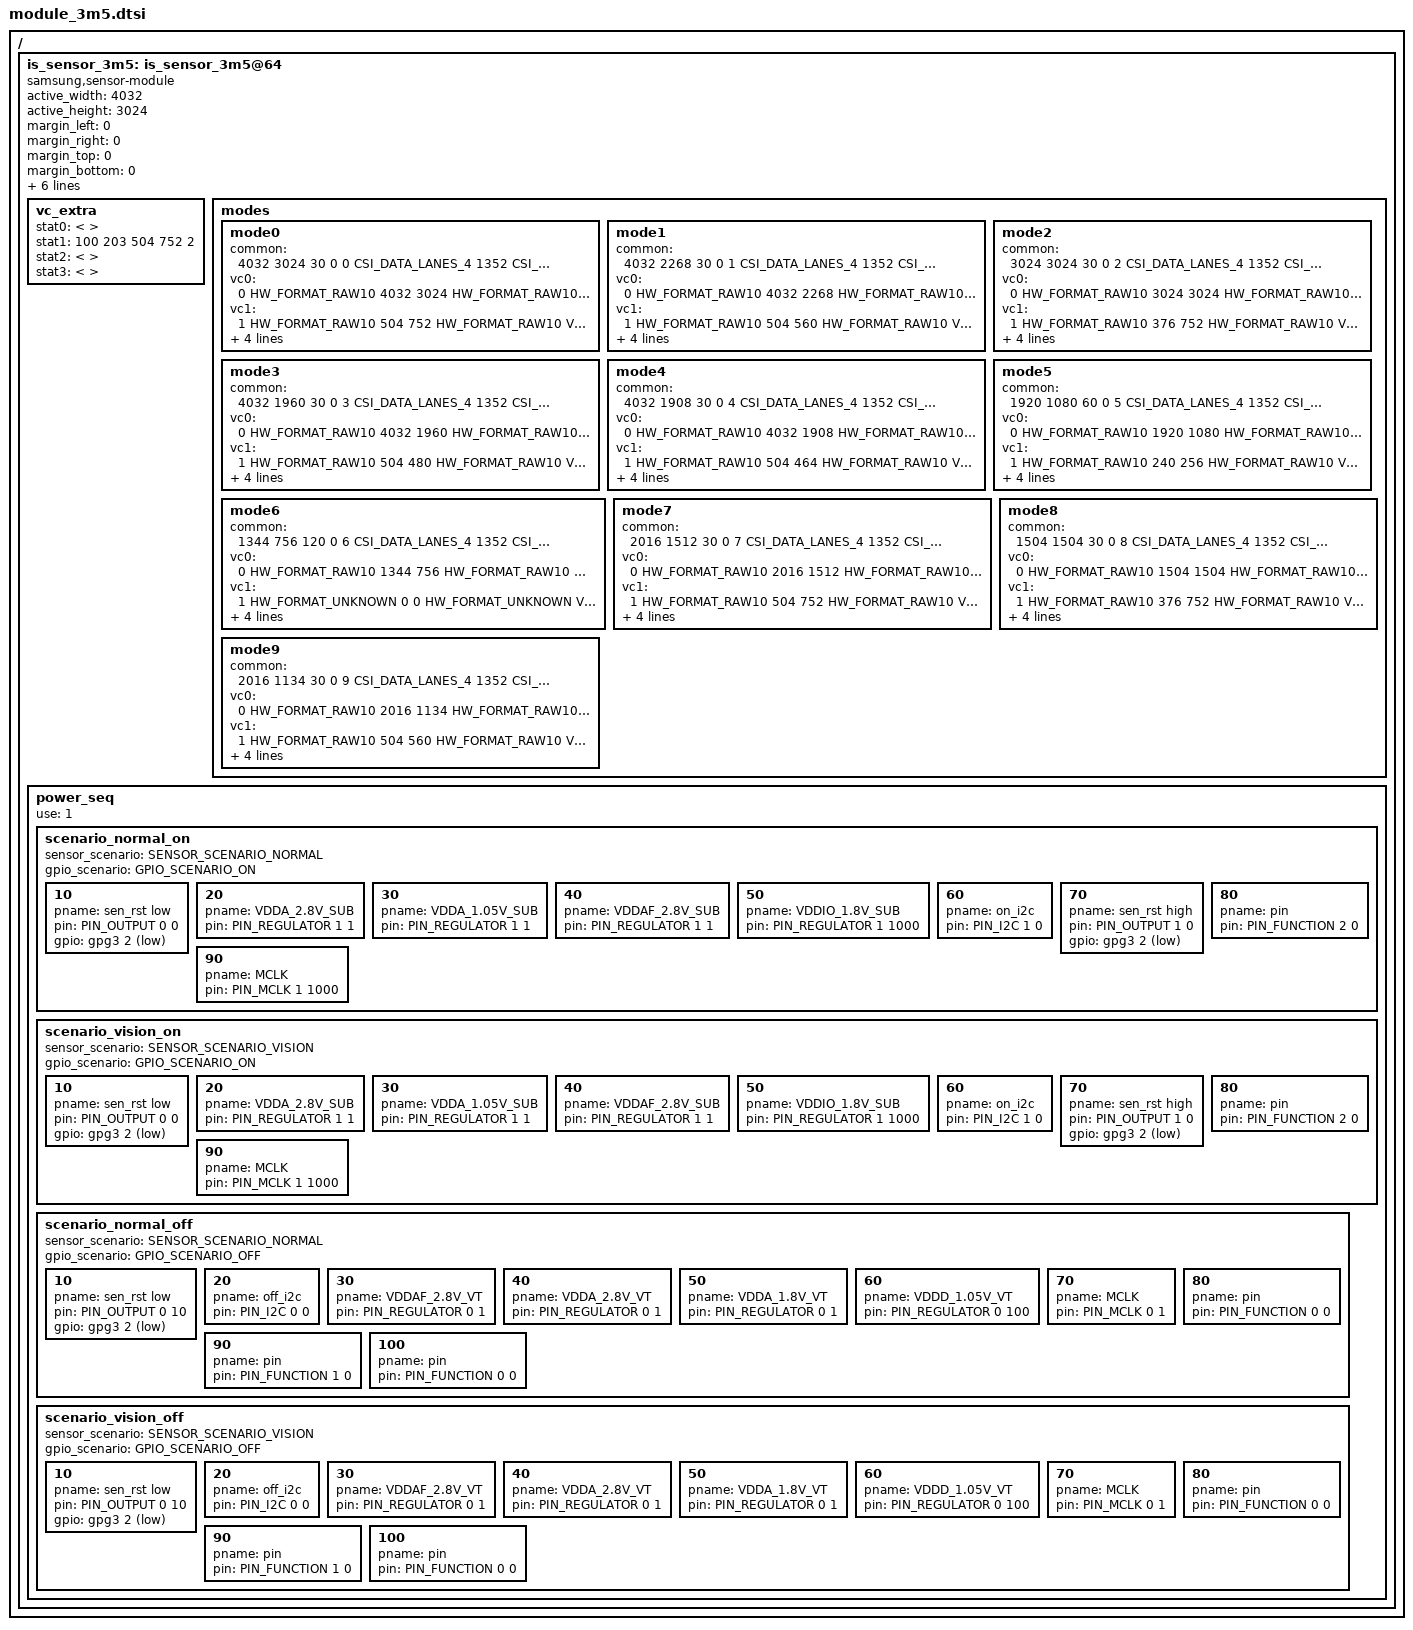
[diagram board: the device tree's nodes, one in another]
/*
 * SAMSUNG EXYNOSxxxx board camera device tree source
 *
 * Copyright (c) 2020 Samsung Electronics Co., Ltd.
 *		http://www.samsung.com
 *
 * This program is free software; you can redistribute it and/or modify
 * it under the terms of the GNU General Public License version 2 as
 * published by the Free Software Foundation.
 */

#include <dt-bindings/camera/exynos_is_dt.h>

/ {
	fragment@camera {
		target-path = "/";
		__overlay__ {
			is_sensor_3m5: is_sensor_3m5@64 {
				compatible = "samsung,sensor-module";

				/* common */
				active_width = <4032>;
				active_height = <3024>;
				margin_left = <0>;
				margin_right = <0>;
				margin_top = <0>;
				margin_bottom = <0>;
				max_framerate = <120>;
				bitwidth = <10>;
				use_retention_mode = <SENSOR_RETENTION_INACTIVE>;
				sensor_maker = "SLSI";
				sensor_name = "3M5";
				setfile_name = "setfile_3m5.bin";

				status = "okay";

				vc_extra {
					/* ex) statX = <stat_type, sensor_mode, max_width, max_height, max_element> */
					stat0 = </* not avaliable */>;	/* VC_BUF_DATA_TYPE_SENSOR_STAT1 */
					stat1 = </* VC_STAT_TYPE_TAIL_FOR_SW_PDAF */ 100 /* VC_SENSOR_MODE_MSPD_SUPER_TAIL */ 203 504 752 2>; /* VC_BUF_DATA_TYPE_GENERAL_STAT1 */
					stat2 = </* not avaliable */>;	/* VC_BUF_DATA_TYPE_SENSOR_STAT2 */
					stat3 = </* not avaliable */>;	/* VC_BUF_DATA_TYPE_GENERAL_STAT2 */
				};

				/* sensor modes */
				modes {
						/* common = <width, height, fps, settle, mode, lane, speed, interleave, lrte, pd_mode> */
						/* vcX = <map, hwformat, width, height, hwformat, type, width, height> */
					mode0 {
						common = <4032 3024 30 0 0 CSI_DATA_LANES_4 1352 CSI_MODE_VC_ONLY LRTE_DISABLE PD_NONE EX_NONE>;
						vc0 = </* in */ 0 HW_FORMAT_RAW10 4032 3024	/* out */ HW_FORMAT_RAW10 VC_NOTHING 4032 3024>;
						vc1 = </* in */ 1 HW_FORMAT_RAW10 504 752	/* out */ HW_FORMAT_RAW10 VC_TAILPDAF 504 752>;
						vc2 = </* in */ 2 HW_FORMAT_UNKNOWN 0 0		/* out */ HW_FORMAT_UNKNOWN VC_NOTHING 0 0>;
						vc3 = </* in */ 3 HW_FORMAT_UNKNOWN 0 0		/* out */ HW_FORMAT_UNKNOWN VC_NOTHING 0 0>;
					};
					mode1 {
						common = <4032 2268 30 0 1 CSI_DATA_LANES_4 1352 CSI_MODE_VC_ONLY LRTE_DISABLE PD_NONE EX_NONE>;
						vc0 = </* in */ 0 HW_FORMAT_RAW10 4032 2268	/* out */ HW_FORMAT_RAW10 VC_NOTHING 4032 2268>;
						vc1 = </* in */ 1 HW_FORMAT_RAW10 504 560	/* out */ HW_FORMAT_RAW10 VC_TAILPDAF 504 560>;
						vc2 = </* in */ 2 HW_FORMAT_UNKNOWN 0 0		/* out */ HW_FORMAT_UNKNOWN VC_NOTHING 0 0>;
						vc3 = </* in */ 3 HW_FORMAT_UNKNOWN 0 0		/* out */ HW_FORMAT_UNKNOWN VC_NOTHING 0 0>;
					};
					mode2 {
						common = <3024 3024 30 0 2 CSI_DATA_LANES_4 1352 CSI_MODE_VC_ONLY LRTE_DISABLE PD_NONE EX_NONE>;
						vc0 = </* in */ 0 HW_FORMAT_RAW10 3024 3024	/* out */ HW_FORMAT_RAW10 VC_NOTHING 3024 3024>;
						vc1 = </* in */ 1 HW_FORMAT_RAW10 376 752	/* out */ HW_FORMAT_RAW10 VC_TAILPDAF 376 752>;
						vc2 = </* in */ 2 HW_FORMAT_UNKNOWN 0 0		/* out */ HW_FORMAT_UNKNOWN VC_NOTHING 0 0>;
						vc3 = </* in */ 3 HW_FORMAT_UNKNOWN 0 0		/* out */ HW_FORMAT_UNKNOWN VC_NOTHING 0 0>;
					};
					mode3 {
						common = <4032 1960 30 0 3 CSI_DATA_LANES_4 1352 CSI_MODE_VC_ONLY LRTE_DISABLE PD_NONE EX_NONE>;
						vc0 = </* in */ 0 HW_FORMAT_RAW10 4032 1960	/* out */ HW_FORMAT_RAW10 VC_NOTHING 4032 1960>;
						vc1 = </* in */ 1 HW_FORMAT_RAW10 504 480	/* out */ HW_FORMAT_RAW10 VC_TAILPDAF 504 480>;
						vc2 = </* in */ 2 HW_FORMAT_UNKNOWN 0 0		/* out */ HW_FORMAT_UNKNOWN VC_NOTHING 0 0>;
						vc3 = </* in */ 3 HW_FORMAT_UNKNOWN 0 0		/* out */ HW_FORMAT_UNKNOWN VC_NOTHING 0 0>;
					};
					mode4 {
						common = <4032 1908 30 0 4 CSI_DATA_LANES_4 1352 CSI_MODE_VC_ONLY LRTE_DISABLE PD_NONE EX_NONE>;
						vc0 = </* in */ 0 HW_FORMAT_RAW10 4032 1908	/* out */ HW_FORMAT_RAW10 VC_NOTHING 4032 1908>;
						vc1 = </* in */ 1 HW_FORMAT_RAW10 504 464	/* out */ HW_FORMAT_RAW10 VC_TAILPDAF 504 464>;
						vc2 = </* in */ 2 HW_FORMAT_UNKNOWN 0 0		/* out */ HW_FORMAT_UNKNOWN VC_NOTHING 0 0>;
						vc3 = </* in */ 3 HW_FORMAT_UNKNOWN 0 0		/* out */ HW_FORMAT_UNKNOWN VC_NOTHING 0 0>;
					};
					mode5 {
						common = <1920 1080 60 0 5 CSI_DATA_LANES_4 1352 CSI_MODE_VC_ONLY LRTE_DISABLE PD_NONE EX_NONE>;
						vc0 = </* in */ 0 HW_FORMAT_RAW10 1920 1080	/* out */ HW_FORMAT_RAW10 VC_NOTHING 1920 1080>;
						vc1 = </* in */ 1 HW_FORMAT_RAW10 240 256	/* out */ HW_FORMAT_RAW10 VC_TAILPDAF 240 256>;
						vc2 = </* in */ 2 HW_FORMAT_UNKNOWN 0 0		/* out */ HW_FORMAT_UNKNOWN VC_NOTHING 0 0>;
						vc3 = </* in */ 3 HW_FORMAT_UNKNOWN 0 0		/* out */ HW_FORMAT_UNKNOWN VC_NOTHING 0 0>;
					};
					mode6 {
						common = <1344 756 120 0 6 CSI_DATA_LANES_4 1352 CSI_MODE_VC_ONLY LRTE_DISABLE PD_NONE EX_NONE>;
						vc0 = </* in */ 0 HW_FORMAT_RAW10 1344 756	/* out */ HW_FORMAT_RAW10 VC_NOTHING 1344 756>;
						vc1 = </* in */ 1 HW_FORMAT_UNKNOWN 0 0		/* out */ HW_FORMAT_UNKNOWN VC_NOTHING 0 0>;
						vc2 = </* in */ 2 HW_FORMAT_UNKNOWN 0 0		/* out */ HW_FORMAT_UNKNOWN VC_NOTHING 0 0>;
						vc3 = </* in */ 3 HW_FORMAT_UNKNOWN 0 0		/* out */ HW_FORMAT_UNKNOWN VC_NOTHING 0 0>;
					};
					mode7 {
						common = <2016 1512 30 0 7 CSI_DATA_LANES_4 1352 CSI_MODE_VC_ONLY LRTE_DISABLE PD_NONE EX_NONE>;
						vc0 = </* in */ 0 HW_FORMAT_RAW10 2016 1512	/* out */ HW_FORMAT_RAW10 VC_NOTHING 2016 1512>;
						vc1 = </* in */ 1 HW_FORMAT_RAW10 504 752	/* out */ HW_FORMAT_RAW10 VC_TAILPDAF 504 752>;
						vc2 = </* in */ 2 HW_FORMAT_UNKNOWN 0 0		/* out */ HW_FORMAT_UNKNOWN VC_NOTHING 0 0>;
						vc3 = </* in */ 3 HW_FORMAT_UNKNOWN 0 0		/* out */ HW_FORMAT_UNKNOWN VC_NOTHING 0 0>;
					};
					mode8 {
						common = <1504 1504 30 0 8 CSI_DATA_LANES_4 1352 CSI_MODE_VC_ONLY LRTE_DISABLE PD_NONE EX_NONE>;
						vc0 = </* in */ 0 HW_FORMAT_RAW10 1504 1504	/* out */ HW_FORMAT_RAW10 VC_NOTHING 1504 1504>;
						vc1 = </* in */ 1 HW_FORMAT_RAW10 376 752	/* out */ HW_FORMAT_RAW10 VC_TAILPDAF 376 752>;
						vc2 = </* in */ 2 HW_FORMAT_UNKNOWN 0 0		/* out */ HW_FORMAT_UNKNOWN VC_NOTHING 0 0>;
						vc3 = </* in */ 3 HW_FORMAT_UNKNOWN 0 0		/* out */ HW_FORMAT_UNKNOWN VC_NOTHING 0 0>;
					};
					mode9 {
						common = <2016 1134 30 0 9 CSI_DATA_LANES_4 1352 CSI_MODE_VC_ONLY LRTE_DISABLE PD_NONE EX_NONE>;
						vc0 = </* in */ 0 HW_FORMAT_RAW10 2016 1134	/* out */ HW_FORMAT_RAW10 VC_NOTHING 2016 1134>;
						vc1 = </* in */ 1 HW_FORMAT_RAW10 504 560	/* out */ HW_FORMAT_RAW10 VC_TAILPDAF 504 560>;
						vc2 = </* in */ 2 HW_FORMAT_UNKNOWN 0 0		/* out */ HW_FORMAT_UNKNOWN VC_NOTHING 0 0>;
						vc3 = </* in */ 3 HW_FORMAT_UNKNOWN 0 0		/* out */ HW_FORMAT_UNKNOWN VC_NOTHING 0 0>;
					};
				};


				power_seq {
					use = <1>;
					scenario_normal_on {
						sensor_scenario = <SENSOR_SCENARIO_NORMAL>;
						gpio_scenario = <GPIO_SCENARIO_ON>;

						/* A start node number should be over the 10 for reserved number 0~9. */
						/* pname = "name"; pin = <act value dealy voltage>; gpio = <gpx# # 0x1>; */
						10 { pname = "sen_rst low"; pin = <PIN_OUTPUT 0 0>; gpio = <&gpg3 2 0x1>; };
						20 { pname = "VDDA_2.8V_SUB"; pin = <PIN_REGULATOR 1 1>; };
						30 { pname = "VDDA_1.05V_SUB"; pin = <PIN_REGULATOR 1 1>; };
						40 { pname = "VDDAF_2.8V_SUB"; pin = <PIN_REGULATOR 1 1>; };
						50 { pname = "VDDIO_1.8V_SUB"; pin = <PIN_REGULATOR 1 1000>; };
						60 { pname = "on_i2c"; pin = <PIN_I2C 1 0>; };
						70 { pname = "sen_rst high"; pin = <PIN_OUTPUT 1 0>; gpio = <&gpg3 2 0x1>; };
						80 { pname = "pin"; pin = <PIN_FUNCTION 2 0>; };
						90 { pname = "MCLK"; pin = <PIN_MCLK 1 1000>; };
					};

					scenario_vision_on {
						sensor_scenario = <SENSOR_SCENARIO_VISION>;
						gpio_scenario = <GPIO_SCENARIO_ON>;

						/* A start node number should be over the 10 for reserved number 0~9. */
						/* pname = "name"; pin = <act value dealy voltage>; gpio = <gpx# # 0x1>; */
						10 { pname = "sen_rst low"; pin = <PIN_OUTPUT 0 0>; gpio = <&gpg3 2 0x1>; };
						20 { pname = "VDDA_2.8V_SUB"; pin = <PIN_REGULATOR 1 1>; };
						30 { pname = "VDDA_1.05V_SUB"; pin = <PIN_REGULATOR 1 1>; };
						40 { pname = "VDDAF_2.8V_SUB"; pin = <PIN_REGULATOR 1 1>; };
						50 { pname = "VDDIO_1.8V_SUB"; pin = <PIN_REGULATOR 1 1000>; };
						60 { pname = "on_i2c"; pin = <PIN_I2C 1 0>; };
						70 { pname = "sen_rst high"; pin = <PIN_OUTPUT 1 0>; gpio = <&gpg3 2 0x1>; };
						80 { pname = "pin"; pin = <PIN_FUNCTION 2 0>; };
						90 { pname = "MCLK"; pin = <PIN_MCLK 1 1000>; };
					};

					scenario_normal_off {
						sensor_scenario = <SENSOR_SCENARIO_NORMAL>;
						gpio_scenario = <GPIO_SCENARIO_OFF>;

						/* A start node number should be over the 10 for reserved number 0~9. */
						/* pname = "name"; pin = <act value dealy voltage>; gpio = <gpx# # 0x1>; */
						10 { pname = "sen_rst low"; pin = <PIN_OUTPUT 0 10>; gpio = <&gpg3 2 0x1>; };
						20 { pname = "off_i2c"; pin = <PIN_I2C 0 0>; };
						30 { pname = "VDDAF_2.8V_VT"; pin = <PIN_REGULATOR 0 1>; };
						40 { pname = "VDDA_2.8V_VT"; pin = <PIN_REGULATOR 0 1>; };
						50 { pname = "VDDA_1.8V_VT"; pin = <PIN_REGULATOR 0 1>; };
						60 { pname = "VDDD_1.05V_VT"; pin = <PIN_REGULATOR 0 100>; };
						70 { pname = "MCLK"; pin = <PIN_MCLK 0 1>; };
						80 { pname = "pin"; pin = <PIN_FUNCTION 0 0>; };
						90 { pname = "pin"; pin = <PIN_FUNCTION 1 0>; };
						100 { pname = "pin"; pin = <PIN_FUNCTION 0 0>; };
					};

					scenario_vision_off {
						sensor_scenario = <SENSOR_SCENARIO_VISION>;
						gpio_scenario = <GPIO_SCENARIO_OFF>;

						/* A start node number should be over the 10 for reserved number 0~9. */
						/* pname = "name"; pin = <act value dealy voltage>; gpio = <gpx# # 0x1>; */
						10 { pname = "sen_rst low"; pin = <PIN_OUTPUT 0 10>; gpio = <&gpg3 2 0x1>; };
						20 { pname = "off_i2c"; pin = <PIN_I2C 0 0>; };
						30 { pname = "VDDAF_2.8V_VT"; pin = <PIN_REGULATOR 0 1>; };
						40 { pname = "VDDA_2.8V_VT"; pin = <PIN_REGULATOR 0 1>; };
						50 { pname = "VDDA_1.8V_VT"; pin = <PIN_REGULATOR 0 1>; };
						60 { pname = "VDDD_1.05V_VT"; pin = <PIN_REGULATOR 0 100>; };
						70 { pname = "MCLK"; pin = <PIN_MCLK 0 1>; };
						80 { pname = "pin"; pin = <PIN_FUNCTION 0 0>; };
						90 { pname = "pin"; pin = <PIN_FUNCTION 1 0>; };
						100 { pname = "pin"; pin = <PIN_FUNCTION 0 0>; };
					};
				};
			};
		}; /* end of __overlay__ */
	}; /* end of fragment */
}; /* end of root */
